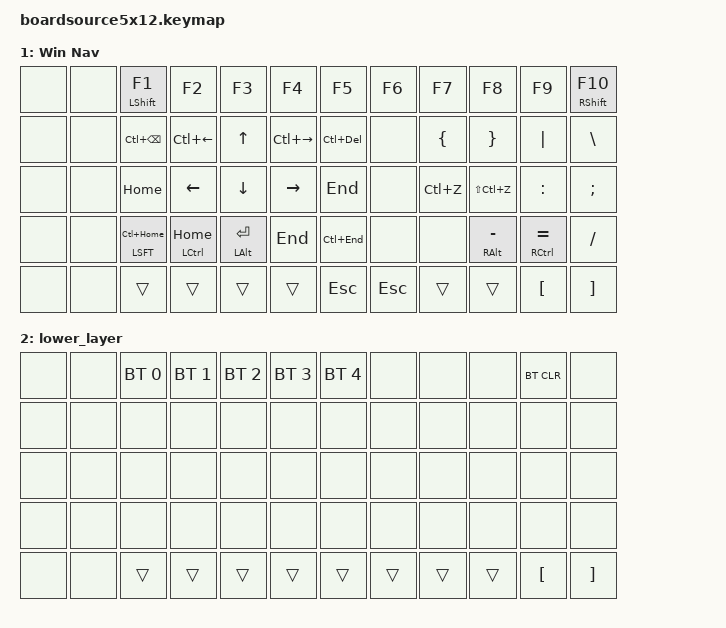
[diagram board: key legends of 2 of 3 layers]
/*
 * Copyright (c) 2021 The ZMK Contributors
 *
 * SPDX-License-Identifier: MIT
 */
 
#include <behaviors.dtsi>
#include <dt-bindings/zmk/keys.h>
#include <dt-bindings/zmk/bt.h>
#include <dt-bindings/zmk/outputs.h>

&mt {
    retro-tap;
};

/ {
	behaviors {
		sh: shift {
			compatible = "zmk,behavior-hold-tap";
			label = "shift mod";
			#binding-cells = <2>;
			tapping_term_ms = <150>;
			flavor = "hold-preferred";
			bindings = <&kp>, <&kp>;
		};
		      bhm: balanced_homerow_mods {
		            compatible = "zmk,behavior-hold-tap";
		            #binding-cells = <2>;
		            tapping-term-ms = <200>;    // <---[[moderate duration]]
		            quick-tap-ms = <0>;
		            flavor = "balanced";
		            bindings = <&kp>, <&kp>;
		        };

	};
	keymap {
		compatible = "zmk,keymap";

		default_layer {
			// ------------------------------------------------------------------------------------------
			// |  ESC  |  1   |  2   |  3   |  4   |  5   |   6   |  7    |  8   |  9   |   0   | BSPC  |
			// |  TAB  |  Q   |  W   |  E   |  R   |  T   |   Y   |  U    |  I   |  O   |   P   |  \    |
			// | SHIFT |  A   |  S   |  D   |  F   |  G   |   H   |  J    |  K   |  L   |   ;   |  '    |
			// | CTRL  |  Z   |  X   |  C   |  V   |  B   |   N   |  M    |  ,   |  .   |   /   | ENTER |
			// |ADJUST | LCTL | LALT | LGUI | LOWR | SPACE| SPACE |  RAIS | LARW | DARW | UARW  | RARW  |

			bindings = <
&none	&none	&kp N1		&kp N2		&kp N3		&kp N4		&kp N5		&kp N6		&kp N7		&kp N8		&kp N9 		&lt 2 N0
&none	&none	&kp Q		&kp W		&kp E		&kp R		&kp T		&kp Y		&kp U		&kp I		&kp O		&kp P
&none	&none   &kp A  		&kp LGUI S  	&kp  D  	&kp F		&kp G   	&kp H      	&kp J   	&kp K   	&kp  L   	&kp APOS
&none	&none	&mt LSHIFT Z	&kp X		&kp C		&kp V		&kp B		&kp N		&kp M		&kp COMMA	&kp DOT		&mt RSHIFT FSLH
&none	&none	&mt LCTRL LBKT	&mt LALT RBKT	&kp LGUI	&mo 1		&mt LCTRL BKSP	&kp SPACE	&kp ENTER	&mt RALT SEMI	&mt RALT MINUS	&mt RCTRL EQL
			>;
		};

	nav_layer {
	label = "Win Nav";
	bindings = <
&none	&none	&mt LSHIFT F1		&kp F2		&kp F3		&kp F4		&kp F5		&kp F6		&kp F7 		&kp F8 		&kp F9 		&mt RSHIFT F10
&none	&none	&kp LC(BSPC) 		&kp LC(LEFT)	&kp UP		&kp LC(RIGHT)	&kp LC(DEL)	&none		&kp LBRC	&kp RBRC 	&kp PIPE	&kp BSLH
&none	&none	&kp HOME		&kp LEFT	&kp DOWN	&kp RIGHT	&kp END		&none		&kp LC(Z)	&kp LS(LC(Z))	&kp COLON	&kp SEMI 
&none	&none	&sh LSFT LC(HOME)	&bhm LCTRL HOME &bhm LALT RET	&kp END		&kp LC(END)	&none		&none		&bhm RALT MINUS	&bhm RCTRL EQL	&kp FSLH 
&none	&none	&trans			&trans		&trans		&trans		&kp ESC		&kp ESC 	&trans		&trans		&kp LBKT	&kp RBKT
	>;
};

		lower_layer {
			// -------------------------------------------------------------------------------------------
			// |  ESC  |  F2  |  F3  |  F4  |  F5  |  F6  |   F7  |  F8   |  F9  | F10  |  F11  |  F12  |
			// |   ~   |  !   |  @   |  #   |  $   |  %   |   ^   |	&   |  *   |  (   |   )   |  DEL  |
			// |       |  F1  |  F2  |  F3  |  F4  |  F5  |   F6  |   _   |  +   |  {   |   }   |   |   |
			// |       |  F7  |  F8  |  F9  |  F10 |  F11 |   F12 | LS(#) |LS(|) |      |       |       |
			// |       |      |      |      |      |      |       |       | NEXT | Vol- | Vol+ | PLAY   |
			bindings = <
&none	&none	&bt BT_SEL 0	&bt BT_SEL 1	&bt BT_SEL 2	&bt BT_SEL 3	&bt BT_SEL 4	&none	&none		&none		&bt BT_CLR	&none
&none	&none	&none		&none		&none		&none		&none		&none	&none		&none		&none		&none		
&none	&none	&none		&none		&none		&none		&none		&none	&none		&none		&none		&none		
&none	&none	&none		&none		&none		&none		&none		&none	&none		&none		&none		&none		
&none	&none	&trans		&trans		&trans		&trans		&trans		&trans 	&trans		&trans		&kp LBKT	&kp RBKT
			>;	 
		};
	};
	

	// ------------------------------------------------------------------------------------------
	// |  0	| 1 	||  2	|  3	|  4	|  5	|  6	|  7	|  8	|  9	| 10	| 11	| 
	// | 12	| 13	|| 14 	| 15	| 16	| 17	| 18	| 19	| 20	| 21	| 22 	| 23	|
	// | 24	| 25	|| 26	| 27	| 28	| 29	| 30	| 31	| 32	| 33	| 34	| 35	|
	// | 36	| 37	|| 38	| 39	| 40	| 41 	| 42	| 43	| 44	| 45	| 46	| 47	|
	// | 48	| 49	|| 50	| 51	| 52	| 53	| 54	| 55	| 56	| 57 	| 58	| 59 	| 


	// ------------------------------------------------------------------------------------------
	// Combos
	// ESC: QWERT
	// Tilde: QWE
	// Tab: QW
	// USB/BT: Bottom right and Q
	// BT CLR: Bottom Right and 0
	// BT 0-4: Bottom right and 1-5
	// Enter: L and '
	// Enter: j and k
	// Alt: . and Right Shfit
	// 

	combos {
		compatible = "zmk,combos";
		combo_esc {
			timeout-ms = <50>;
			key-positions = <54 55>;
			bindings = <&kp ESC>;
		};
		combo_tilde {
			timeout-ms = <50>;
			key-positions = <14 15 16 >;
			bindings = <&kp TILDE>;
		};
		combo_tab {
			timeout-ms = <50>;
			key-positions = <14 15>;
			bindings = <&kp TAB>;
		};
		combo_ralt {
			timeout-ms = <50>;
			key-positions = <46 47>;
			bindings = <&kp RALT>;
		};
		combo_output {
			timeout-ms = <50>;
			key-positions = <14 59>;
			bindings = <&out OUT_TOG>;
		};
		combo_btclr {
			timeout-ms = <50>;
			key-positions = <11 59>;
			bindings = <&bt BT_CLR>;
		};	
		combo_bt0 {
			timeout-ms = <50>;
			key-positions = <2 59>;
			bindings = <&bt BT_SEL 0>;
		};	
		combo_bt1 {
			timeout-ms = <50>;
			key-positions = <3 59>;
			bindings = <&bt BT_SEL 1>;
		};
		combo_bt2 {
			timeout-ms = <50>;
			key-positions = <4 59>;
			bindings = <&bt BT_SEL 2>;
		};
		combo_bt3 {
			timeout-ms = <50>;
			key-positions = <5 59>;
			bindings = <&bt BT_SEL 3>;
		};
		combo_bt4 {
			timeout-ms = <50>;
			key-positions = <6 59>;
			bindings = <&bt BT_SEL 4>;
		};
		combo_semi {
			timeout-ms = <50>;
			key-positions = <34 35>;
			bindings = <&kp SEMI>;
		};
		combo_enter {
			timeout-ms = <50>;
			key-positions = <32 33>;
			bindings = <&kp ENTER>;
		};
		combo_delwd {
			timeout-ms = <50>;
			key-positions = <28 29>;
			bindings = <&kp LC(BSPC)>;
		};
		combo_cut {
			timeout-ms = <50>;
			key-positions = <38 39>;
			bindings = <&kp LC(X)>;
		};
		combo_copy {
			timeout-ms = <50>;
			key-positions = <39 40>;
			bindings = <&kp LC(C)>;
		};
		combo_paste{
			timeout-ms = <50>;
			key-positions = <40 41>;
			bindings = <&kp LC(V)>;
		};
	};
};
